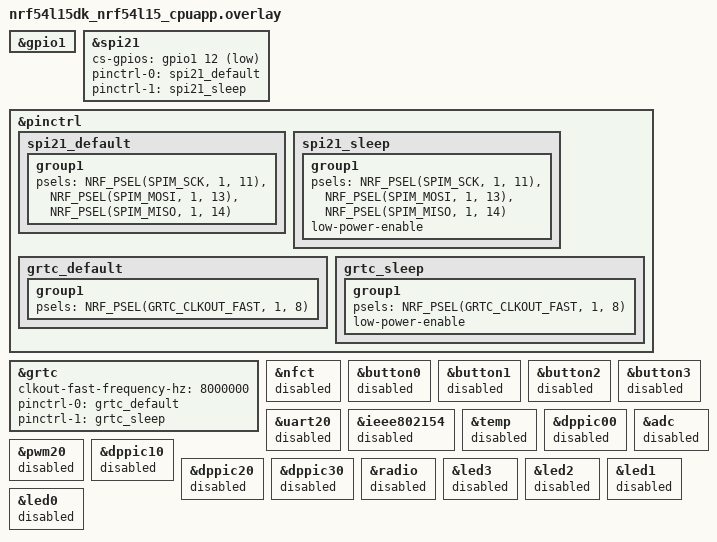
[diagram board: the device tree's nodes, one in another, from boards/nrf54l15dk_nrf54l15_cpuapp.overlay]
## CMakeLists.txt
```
cmake_minimum_required(VERSION 3.20.0)

# Add local devicetree bindings directory
list(APPEND DTS_ROOT ${CMAKE_CURRENT_SOURCE_DIR})

find_package(Zephyr REQUIRED HINTS $ENV{ZEPHYR_BASE})
project(ads131m04)

# Add your application source
target_sources(app PRIVATE
    src/main.c
    src/ads131m04_spi/ads131m04_spi.c
    src/sampling/sampling.c
    src/bluetooth/bluetooth.c
    src/bluetooth/bt_channel.c
    src/bluetooth/bt_ecg.c
    src/ble_log_backend/ble_log_backend.c
)

# Add include directories for module headers
target_include_directories(app PRIVATE
    src/ads131m04_spi
    src/sampling
    src/bluetooth
    src/ble_log_backend
    src/helper
)
```

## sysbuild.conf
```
# Enable MCUboot bootloader for FOTA support
SB_CONFIG_BOOTLOADER_MCUBOOT=y
```

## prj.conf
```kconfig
CONFIG_SPI=y
CONFIG_LOG=y
CONFIG_LOG_DEFAULT_LEVEL=3
CONFIG_LOG_OUTPUT=y
CONFIG_MAIN_STACK_SIZE=2048

# GRTC (Global Real-Time Counter) for 8.192 MHz clock output to ADC
CONFIG_NRF_GRTC_TIMER=y
CONFIG_NRF_GRTC_START_SYSCOUNTER=y

# GPIO support required for CS, SYNC/RESET and DRDY pins
CONFIG_GPIO=y
CONFIG_LOG_BUFFER_SIZE=8192

# Bluetooth Low Energy
CONFIG_BT=y
CONFIG_BT_NUS=y
CONFIG_BT_PERIPHERAL=y
CONFIG_BT_DEVICE_NAME="TENG_Scope"
# 0x0540 = Generic Sensor (BT SIG Assigned Numbers)
CONFIG_BT_DEVICE_APPEARANCE=1344
CONFIG_BT_MAX_CONN=2
CONFIG_BT_GAP_PERIPHERAL_PREF_PARAMS=y

# GATT configuration
CONFIG_BT_GATT_DYNAMIC_DB=y
CONFIG_BT_ATT_PREPARE_COUNT=2

# MTU and buffer configuration for batching (20 samples = 240 bytes)
CONFIG_BT_L2CAP_TX_MTU=247
CONFIG_BT_BUF_ACL_TX_SIZE=251
CONFIG_BT_BUF_ACL_RX_SIZE=251
CONFIG_BT_CTLR_DATA_LENGTH_MAX=251

# Increase stack sizes for BT
CONFIG_SYSTEM_WORKQUEUE_STACK_SIZE=2048
CONFIG_BT_RX_STACK_SIZE=2048

# CPU load monitoring
CONFIG_CPU_LOAD=y

# Heap memory pool for BLE/MCUmgr support
CONFIG_HEAP_MEM_POOL_SIZE=32768

#CONFIG_NFCT_PINS_AS_GPIOS=y

# Nordic MCUmgr BLE OTA DFU - This handles all dependencies automatically
CONFIG_NCS_SAMPLE_MCUMGR_BT_OTA_DFU=y
CONFIG_NCS_SAMPLE_MCUMGR_BT_OTA_DFU_SPEEDUP=y

# Optional: Authentication (recommended for production)
# CONFIG_MCUMGR_TRANSPORT_BT_PERM_RW_AUTHEN=y
```

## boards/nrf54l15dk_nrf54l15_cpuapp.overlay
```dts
// To get started, press Ctrl+Space to bring up the completion menu and view the available nodes.

// You can also use the buttons in the sidebar to perform actions on nodes.
// Actions currently available include:

// * Enabling / disabling the node
// * Adding the bus to a bus
// * Removing the node
// * Connecting ADC channels

// For more help, browse the DeviceTree documentation at https: //docs.zephyrproject.org/latest/guides/dts/index.html
// You can also visit the nRF DeviceTree extension documentation at https: //docs.nordicsemi.com/bundle/nrf-connect-vscode/page/guides/ncs_configure_app.html#devicetree-support-in-the-extension
/* uart20 is being used for serial communication, so use spi21*/

&gpio1 {
    status = "okay";
};

&spi21 {
    status = "okay";
    cs-gpios = <&gpio1 12 GPIO_ACTIVE_LOW>; /* P1.12 ADC */
    pinctrl-0 = <&spi21_default>;
    pinctrl-1 = <&spi21_sleep>;
    pinctrl-names = "default", "sleep";
};



&pinctrl {
    spi21_default: spi21_default {
        group1 {
            psels = <NRF_PSEL(SPIM_SCK, 1, 11)>,   /* P1.11 */
                    <NRF_PSEL(SPIM_MOSI, 1, 13)>,  /* P1.14 */
                    <NRF_PSEL(SPIM_MISO, 1, 14)>;  /* P1.13 */
        };
    };

    spi21_sleep: spi21_sleep {
        group1 {
            psels = <NRF_PSEL(SPIM_SCK, 1, 11)>,
                    <NRF_PSEL(SPIM_MOSI, 1, 13)>,
                    <NRF_PSEL(SPIM_MISO, 1, 14)>;
            low-power-enable;
        };
    };


};

/* Enable GRTC for 8.192 MHz clock output on P1.12 (ADC external clock) */
&grtc {
    status = "okay";
    clkout-fast-frequency-hz = <8000000>;  /* 8.192 MHz */
    pinctrl-0 = <&grtc_default>;
    pinctrl-1 = <&grtc_sleep>;
    pinctrl-names = "default", "sleep";
};

/* Configure GRTC clock output pin */
&pinctrl {
    grtc_default: grtc_default {
        group1 {
            psels = <NRF_PSEL(GRTC_CLKOUT_FAST, 1, 8)>;
        };
    };

    grtc_sleep: grtc_sleep {
        group1 {
            psels = <NRF_PSEL(GRTC_CLKOUT_FAST, 1, 8)>;
            low-power-enable;
        };
    };
};



&nfct {
    status = "disabled";
};


&button0 {
    status = "disabled";
};

/* Disable Button 1 to free P1.09 for ADS131M04 DRDY pin */
&button1 {
    status = "disabled";
};

/* Disable Button 2 to free P1.08 for ADS131M04 clock output */
&button2 {
    status = "disabled";
};

/* Disable Button 3 to free P1.10 for ADS131M04 RESET pin */
&button3 {
    status = "disabled";
};

&uart20 {
    //current-speed = <115200>;
    status = "disabled";
};

&ieee802154 {
    status = "disabled";
};

&nfct {
    status = "disabled";
};

&temp {
    status = "disabled";
};

&dppic00 {
    status = "disabled";
};

&adc {
    status = "disabled";
};

&pwm20 {
    status = "disabled";
};


&dppic10 {
    status = "disabled";
};

&dppic20 {
    status = "disabled";
};

&dppic30 {
    status = "disabled";
};

&radio {
    status = "disabled";
};
&led3 {
    status = "disabled";
};

&led2 {
    status = "disabled";
};

&led1 {
    status = "disabled";
};

&led0 {
    status = "disabled";
};
```

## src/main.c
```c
/*
 * SPDX-License-Identifier: MIT
 * Copyright (c) 2026 Jesper Sjöberg (@repsejs, KTH: @jessjobe)
 * Copyright (c) 2026 Max Gulda (@Max-Gulda, KTH: @gulda)
 */

#include <zephyr/kernel.h>
#include "ads131m04_spi.h"
#include "sampling.h"
#include "bluetooth.h"
#include "ble_log_backend.h"
#include <zephyr/logging/log.h>
#include <zephyr/debug/cpu_load.h>

LOG_MODULE_REGISTER(main, LOG_LEVEL_INF);

int main(void) {
    int err;
    ads131m04_config_t *adc_config;

    LOG_INF("=== ADS131M04 oscilloscope sampling (DRDY-driven) ===");
    
    /* ------------ INIT BLUETOOTH START ------------*/

    /* Initialize Bluetooth */
    err = bluetooth_init();
    if (err < 0) {
        LOG_ERR("Failed to initialize Bluetooth (%d)", err);
        return 0;
    }

    /* Start Bluetooth advertising */
    err = bluetooth_start();
    if (err < 0) {
        LOG_ERR("Failed to start Bluetooth (%d)", err);
        return 0;
    }

    /* Enable BLE log backend — messages stream to any NUS-connected terminal */
    ble_log_backend_enable();

    //k_msleep(20000);
    /* ------------ INIT BLUETOOTH END ------------*/

    /* ------------ INIT ADS131M04 START -------------*/
    /* Get ADC configuration */
    adc_config = ads131m04_get_config();

    /* Perform full ADC setup */
    err = ads131m04_full_setup(adc_config);
    if (err < 0) {
        LOG_ERR("Failed to setup ADC");
        return 0;
    }

    /* ------------ INIT ADS131M04 END --------------*/

    /* ------------ INIT SAMPLING START ------------*/

    /* Initialize sampling system */
    err = sampling_init(adc_config);
    if (err < 0) {
        LOG_ERR("Failed to initialize sampling system");
        return 0;
    }

    /* Start sampling */
    err = sampling_start();
    if (err < 0) {
        LOG_ERR("Failed to start sampling");
        return 0;
    }

    /* ------------ INIT BLUETOOTH END ------------*/
    int cpu_load = 0;

    /* Main thread monitors CPU load */
    while (1) {
        k_msleep(10000);
        cpu_load = cpu_load_get(false);
        if (cpu_load >= 0) {
            LOG_INF("CPU Usage: %d.%d%%", cpu_load / 10, cpu_load % 10);
        } else {
            LOG_ERR("CPU Usage: Error %d", cpu_load);
        }
    }

    return 0;
}
```
